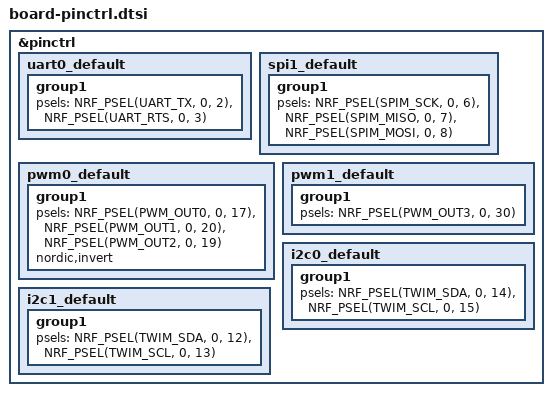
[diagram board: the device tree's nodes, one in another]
&pinctrl {
    uart0_default: uart0_default {
      group1 {
        psels = <NRF_PSEL(UART_TX, 0, 2)>,
                <NRF_PSEL(UART_RTS, 0, 3)>;
      };
    };

    spi1_default: spi1_default {
      group1 {
        psels = <NRF_PSEL(SPIM_SCK, 0, 6)>,
                <NRF_PSEL(SPIM_MISO, 0, 7)>,
                <NRF_PSEL(SPIM_MOSI, 0, 8)>;
      };
    };

    pwm0_default: pwm0_default {
      group1 {
        psels = <NRF_PSEL(PWM_OUT0, 0, 17)>,
                <NRF_PSEL(PWM_OUT1, 0, 20)>,
                <NRF_PSEL(PWM_OUT2, 0, 19)>;
        nordic,invert;
      };
    };

    pwm1_default: pwm1_default {
      group1 {
        psels = <NRF_PSEL(PWM_OUT3, 0, 30)>;
      };
    };
    
    i2c0_default: i2c0_default {
      group1 {
        psels = <NRF_PSEL(TWIM_SDA, 0, 14)>,
                <NRF_PSEL(TWIM_SCL, 0, 15)>;
      };
    };

    i2c1_default: i2c1_default {
      group1 {
        psels = <NRF_PSEL(TWIM_SDA, 0, 12)>,
                <NRF_PSEL(TWIM_SCL, 0, 13)>;
      };
    };    
  };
